# MSP430FR2476 register map
Vendor: msp430gen; File version: v0.4.0-28-gb0087ce-dirty
Registers are 16-bit, read-write, reset 0x0 unless marked. A register's access mark holds for its fields unless they carry their own. Offsets are from the block's base; [hi:lo] are bit positions; {n}, {i} and the like mark numbered series; 'fields as' and 'values as' point back to an identical list.

## E_USCI_B1
Base 0x00000580
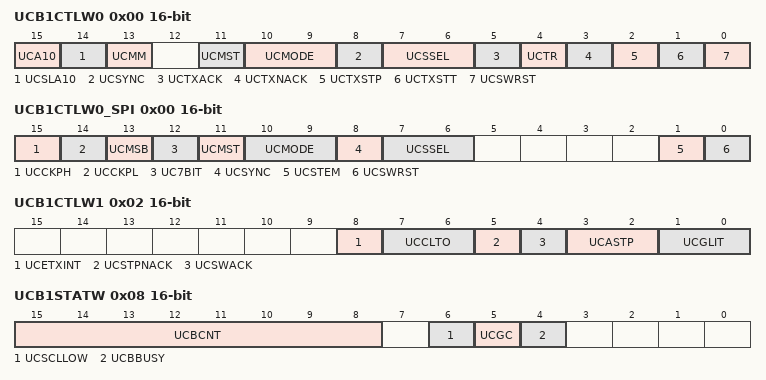
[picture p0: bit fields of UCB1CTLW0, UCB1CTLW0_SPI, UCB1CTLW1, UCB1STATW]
0x00 UCB1CTLW0 — eUSCI_Bx Control Word Register 0
  [15] UCA10 — Own addressing mode select
    0=Own address is a 7-bit address; 1=Own address is a 10-bit address
  [14] UCSLA10 — Slave addressing mode select
    0=7BIT (Address slave with 7-bit address); 1=10BIT (Address slave with 10-bit address)
  [13] UCMM — Multi-master environment select
    0=SINGLE (Single master environment. There is no other master in the system. The address compare unit is disabled.); 1=MULTI (Multi-master environment)
  [11] UCMST — Master mode select
    0=SLAVE (Slave mode); 1=MASTER (Master mode)
  [10:9] UCMODE — eUSCI_B mode
    0=3-pin SPI; 1=4-pin SPI (master or slave enabled if STE = 1); 2=4-pin SPI (master or slave enabled if STE = 0); 3=I2C mode
  [8] UCSYNC — Synchronous mode enable
    0=ASYNC (Asynchronous mode); 1=SYNC (Synchronous mode)
  [7:6] UCSSEL — eUSCI_B clock source select
    0=UCLKI; 1=ACLK; 2=SMCLK; 3=SMCLK
  [5] UCTXACK — Transmit ACK condition in slave mode
    0=Do not acknowledge the slave address; 1=Acknowledge the slave address
  [4] UCTR — Transmitter/receiver
    0=RX (Receiver); 1=TX (Transmitter)
  [3] UCTXNACK — Transmit a NACK
    0=Acknowledge normally; 1=Generate NACK
  [2] UCTXSTP — Transmit STOP condition in master mode
    0=No STOP generated; 1=Generate STOP
  [1] UCTXSTT — Transmit START condition in master mode
    0=Do not generate START condition; 1=Generate START condition
  [0] UCSWRST — Software reset enable
    0=DISABLE (Disabled. eUSCI_B reset released for operation); 1=ENABLE (Enabled. eUSCI_B logic held in reset state)
0x00 UCB1CTLW0_SPI (alternate view of UCB1CTLW0) — eUSCI_Bx Control Word Register 0
  [15] UCCKPH — Clock phase select
    0=Data is changed on the first UCLK edge and captured on the following edge; 1=Data is captured on the first UCLK edge and changed on the following edge
  [14] UCCKPL — Clock polarity select
    0=LOW (The inactive state is low); 1=HIGH (The inactive state is high)
  [13] UCMSB — MSB first select
    0=LSB first; 1=MSB first
  [12] UC7BIT — Character length
    0=8BIT (8-bit data); 1=7BIT (7-bit data)
  [11] UCMST — Master mode select
    0=SLAVE (Slave mode); 1=MASTER (Master mode)
  [10:9] UCMODE — eUSCI mode
    0=3-pin SPI; 1=4-pin SPI with UCxSTE active high: Slave enabled when UCxSTE = 1; 2=4-pin SPI with UCxSTE active low: Slave enabled when UCxSTE = 0; 3=I2C mode
  [8] UCSYNC — Synchronous mode enable
    0=ASYNC (Asynchronous mode); 1=SYNC (Synchronous mode)
  [7:6] UCSSEL — eUSCI_B clock source select
    1=ACLK; 2=SMCLK; 3=SMCLK
  [1] UCSTEM — STE mode select in master mode.
    0=STE pin is used to prevent conflicts with other masters; 1=STE pin is used to generate the enable signal for a 4-wire slave
  [0] UCSWRST — Software reset enable
    values as UCB1CTLW0.UCSWRST
0x02 UCB1CTLW1 — eUSCI_Bx Control Word Register 1
  [8] UCETXINT — Early UCTXIFG0
    0=UCTXIFGx is set after an address match with UCxI2COAx and the direction bit indicating slave transmit; 1=UCTXIFG0 is set for each START condition
  [7:6] UCCLTO — Clock low timeout select
    0=Disable clock low timeout counter; 1=135 000 SYSCLK cycles (approximately 28 ms); 2=150 000 SYSCLK cycles (approximately 31 ms); 3=165 000 SYSCLK cycles (approximately 34 ms)
  [5] UCSTPNACK — ACK all master bytes
    0=Send a non-acknowledge before the STOP condition as a master receiver (conform to I2C standard); 1=All bytes are acknowledged by the eUSCI_B when configured as master receiver
  [4] UCSWACK — SW or HW ACK control
    0=The address acknowledge of the slave is controlled by the eUSCI_B module; 1=The user needs to trigger the sending of the address ACK by issuing UCTXACK
  [3:2] UCASTP — Automatic STOP condition generation
    0=No automatic STOP generation. The STOP condition is generated after the user sets the UCTXSTP bit. The value in UCBxTBCNT is a don't care.; 1=UCBCNTIFG is set with the byte counter reaches the threshold defined in UCBxTBCNT; 2=A STOP condition is generated automatically after the byte counter value reached UCBxTBCNT. UCBCNTIFG is set with the byte counter reaching the threshold
  [1:0] UCGLIT — Deglitch time
    0=50 ns; 1=25 ns; 2=12.5 ns; 3=6.25 ns
0x06 UCB1BRW — eUSCI_Bx Baud Rate Control Word Register
0x06 UCB1BRW_SPI (alternate view of UCB1BRW) — eUSCI_Bx Bit Rate Control Register 1
0x08 UCB1STATW — eUSCI_Bx Status Register
  [15:8] UCBCNT ro — Hardware byte counter value
  [6] UCSCLLOW ro — SCL low
    0=SCL is not held low; 1=SCL is held low
  [5] UCGC ro — General call address received
    0=No general call address received; 1=General call address received
  [4] UCBBUSY ro — Bus busy
    0=IDLE (Bus inactive); 1=BUSY (Bus busy)
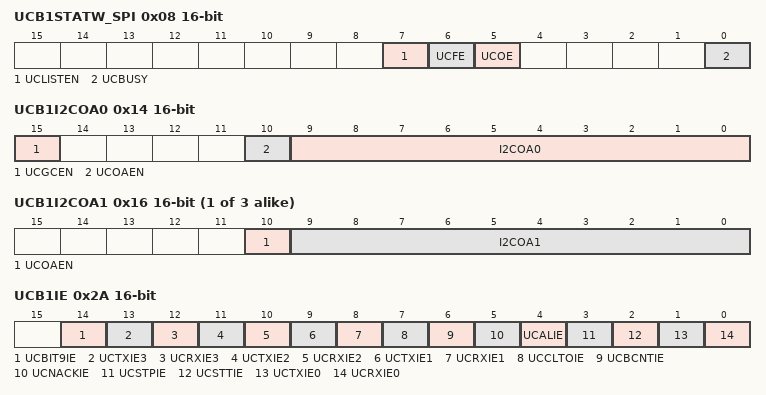
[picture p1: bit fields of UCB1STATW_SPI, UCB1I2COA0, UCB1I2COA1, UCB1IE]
0x08 UCB1STATW_SPI (alternate view of UCB1STATW)
  [7] UCLISTEN — Listen enable
    0=Disabled; 1=Enabled. UCBxTXD is internally fed back to the receiver
  [6] UCFE — Framing error flag
    0=No error; 1=Bus conflict occurred
  [5] UCOE — Overrun error flag
    0=No error; 1=Overrun error occurred
  [0] UCBUSY ro — eUSCI_B1 busy
    0=IDLE (eUSCI_B1 inactive); 1=BUSY (eUSCI_B1 transmitting or receiving)
0x0A UCB1TBCNT — eUSCI_Bx Byte Counter Threshold Register
  [7:0] UCTBCNT — Byte counter threshold value
0x0C UCB1RXBUF — eUSCI_Bx Receive Buffer Register
  [7:0] UCRXBUF ro — Receive data buffer
0x0C UCB1RXBUF_SPI (alternate view of UCB1RXBUF) — eUSCI_Bx Receive Buffer Register
  [7:0] UCRXBUF ro — Receive data buffer
0x0E UCB1TXBUF — eUSCI_Bx Transmit Buffer Register
  [7:0] UCTXBUF — Transmit data buffer
0x0E UCB1TXBUF_SPI (alternate view of UCB1TXBUF) — eUSCI_Bx Transmit Buffer Register
  [7:0] UCTXBUF — Transmit data buffer
0x14 UCB1I2COA0 — eUSCI_Bx I2C Own Address 0 Register
  [15] UCGCEN — General call response enable
    0=Do not respond to a general call; 1=Respond to a general call
  [10] UCOAEN — Own Address enable register
    0=DISABLE (The slave address defined in I2COA0 is disabled); 1=ENABLE (The slave address defined in I2COA0 is enabled)
  [9:0] I2COA0 — I2C own address
{0x14+2i} UCB1I2COA{i} (i=1..3) — eUSCI_Bx I2C Own Address {i} Register
  [10] UCOAEN — Own Address enable register
    0=DISABLE (The slave address defined in I2COA{i} is disabled); 1=ENABLE (The slave address defined in I2COA{i} is enabled)
  [9:0] I2COA{i} — I2C own address
0x1C UCB1ADDRX — eUSCI_Bx I2C Received Address Register
  [9:0] ADDRX ro — Received Address Register
0x1E UCB1ADDMASK — eUSCI_Bx I2C Address Mask Register
  [9:0] ADDMASK — Address Mask Register. By clearing the corresponding bit of the own address, this bit is a don't care when comparing the address on the bus to the own address. Using this method, it is possible to react on more than one slave address. When all bits of ADDMASKx are set, the address mask feature is deactivated. Modify only when UCSWRST = 1.
0x20 UCB1I2CSA — eUSCI_Bx I2C Slave Address Register
  [9:0] I2CSA — I2C slave address
0x2A UCB1IE — eUSCI_Bx Interrupt Enable Register
  [all] fields
    0=Interrupt disabled; 1=Interrupt enabled
  [14] UCBIT9IE — Bit position 9 interrupt enable
  [13] UCTXIE3 — Transmit interrupt enable 3
  [12] UCRXIE3 — Receive interrupt enable 3
  [11] UCTXIE2 — Transmit interrupt enable 2
  [10] UCRXIE2 — Receive interrupt enable 2
  [9] UCTXIE1 — Transmit interrupt enable 1
  [8] UCRXIE1 — Receive interrupt enable 1
  [7] UCCLTOIE — Clock low timeout interrupt enable
  [6] UCBCNTIE — Byte counter interrupt enable
  [5] UCNACKIE — Not-acknowledge interrupt enable
  [4] UCALIE — Arbitration lost interrupt enable
  [3] UCSTPIE — STOP condition interrupt enable
  [2] UCSTTIE — START condition interrupt enable
  [1] UCTXIE0 — Transmit interrupt enable 0
  [0] UCRXIE0 — Receive interrupt enable 0
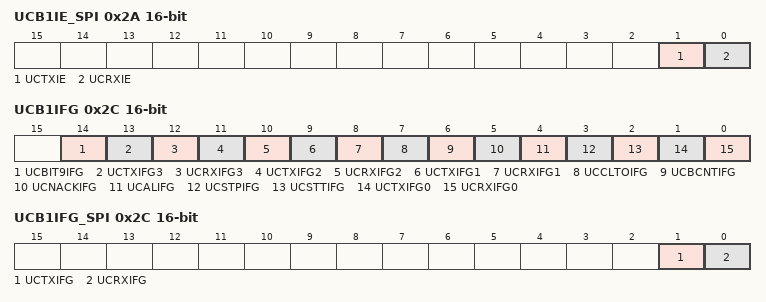
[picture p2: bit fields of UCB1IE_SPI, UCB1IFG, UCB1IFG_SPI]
0x2A UCB1IE_SPI (alternate view of UCB1IE) — eUSCI_Bx Interrupt Enable Register
  [1] UCTXIE — Transmit interrupt enable
    0=Interrupt disabled; 1=Interrupt enabled
  [0] UCRXIE — Receive interrupt enable
    0=Interrupt disabled; 1=Interrupt enabled
0x2C UCB1IFG — eUSCI_Bx Interrupt Flag Register
  [all] fields
    0=No interrupt pending; 1=Interrupt pending
  [14] UCBIT9IFG — Bit position 9 interrupt flag
  [13] UCTXIFG3 — eUSCI_B transmit interrupt flag 3
  [12] UCRXIFG3 — eUSCI_B receive interrupt flag 3
  [11] UCTXIFG2 — eUSCI_B transmit interrupt flag 2
  [10] UCRXIFG2 — eUSCI_B receive interrupt flag 2
  [9] UCTXIFG1 — eUSCI_B transmit interrupt flag 1
  [8] UCRXIFG1 — eUSCI_B receive interrupt flag 1
  [7] UCCLTOIFG — Clock low timeout interrupt flag
  [6] UCBCNTIFG — Byte counter interrupt flag
  [5] UCNACKIFG — Not-acknowledge received interrupt flag
  [4] UCALIFG — Arbitration lost interrupt flag
  [3] UCSTPIFG — STOP condition interrupt flag
  [2] UCSTTIFG — START condition interrupt flag
  [1] UCTXIFG0 — eUSCI_B transmit interrupt flag 0
  [0] UCRXIFG0 — eUSCI_B receive interrupt flag 0
0x2C UCB1IFG_SPI (alternate view of UCB1IFG) — eUSCI_Bx Interrupt Flag Register
  [1] UCTXIFG — Transmit interrupt flag
    0=No interrupt pending; 1=Interrupt pending
  [0] UCRXIFG — Receive interrupt flag
    0=No interrupt pending; 1=Interrupt pending
0x2E UCB1IV — eUSCI_Bx Interrupt Vector Register
  [15:0] UCIV ro — eUSCI_B interrupt vector value
    0=NONE (No interrupt pending); 2=UCALIFG (Interrupt Source: Arbitration lost; Interrupt Flag: UCALIFG; Interrupt Priority: Highest); 4=UCNACKIFG (Interrupt Source: Not acknowledgment; Interrupt Flag: UCNACKIFG); 6=UCSTTIFG (Interrupt Source: Start condition received; Interrupt Flag: UCSTTIFG); 8=UCSTPIFG (Interrupt Source: Stop condition received; Interrupt Flag: UCSTPIFG); 10=UCRXIFG3 (Interrupt Source: Slave 3 Data received; Interrupt Flag: UCRXIFG3); 12=UCTXIFG3 (Interrupt Source: Slave 3 Transmit buffer empty; Interrupt Flag: UCTXIFG3); 14=UCRXIFG2 (Interrupt Source: Slave 2 Data received; Interrupt Flag: UCRXIFG2); 16=UCTXIFG2 (Interrupt Source: Slave 2 Transmit buffer empty; Interrupt Flag: UCTXIFG2); 18=UCRXIFG1 (Interrupt Source: Slave 1 Data received; Interrupt Flag: UCRXIFG1); 20=UCTXIFG1 (Interrupt Source: Slave 1 Transmit buffer empty; Interrupt Flag: UCTXIFG1); 22=UCRXIFG0 (Interrupt Source: Data received; Interrupt Flag: UCRXIFG0); 24=UCTXIFG0 (Interrupt Source: Transmit buffer empty; Interrupt Flag: UCTXIFG0); 26=UCBCNTIFG (Interrupt Source: Byte counter zero; Interrupt Flag: UCBCNTIFG); 28=UCCLTOIFG (Interrupt Source: Clock low timeout; Interrupt Flag: UCCLTOIFG); 30=UCBIT9IFG (Interrupt Source: Nineth bit position; Interrupt Flag: UCBIT9IFG; Priority: Lowest)
0x2E UCB1IV_SPI (alternate view of UCB1IV) — eUSCI_Bx Interrupt Vector Register
  [15:0] UCIV ro — eUSCI_B interrupt vector value
    0=NONE (No interrupt pending); 2=UCRXIFG (Interrupt Source: Data received; Interrupt Flag: UCRXIFG; Interrupt Priority: Highest); 4=UCTXIFG (Interrupt Source: Transmit buffer empty; Interrupt Flag: UCTXIFG; Interrupt Priority: Lowest)
